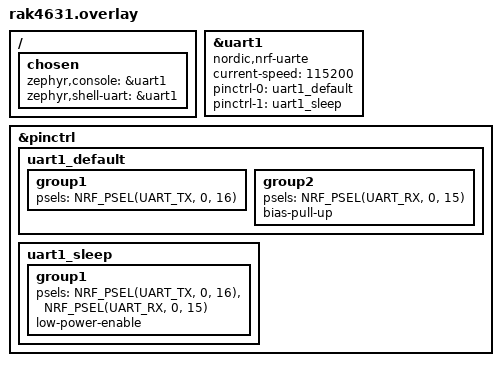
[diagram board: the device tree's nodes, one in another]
/*
 * Motor driver test - Node (Link) Y channel
 * Console: uart1 (P0.16 TX / P0.15 RX) @ 115200 → ttyUSB0
 *
 * Y channel:
 *   Y_EN_A  = P0.25
 *   Y_EN_B  = P1.01
 *   Y_EN_P2 = P1.02 (반드시 LOW 유지)
 *   12V_EN  = P0.17
 *
 * 참고: link.h
 */

/ {
	chosen {
		zephyr,console = &uart1;
		zephyr,shell-uart = &uart1;
	};
};

&uart1 {
	compatible = "nordic,nrf-uarte";
	status = "okay";
	current-speed = <115200>;
	pinctrl-0 = <&uart1_default>;
	pinctrl-1 = <&uart1_sleep>;
	pinctrl-names = "default", "sleep";
};

&pinctrl {
	uart1_default: uart1_default {
		group1 {
			psels = <NRF_PSEL(UART_TX, 0, 16)>;
		};
		group2 {
			psels = <NRF_PSEL(UART_RX, 0, 15)>;
			bias-pull-up;
		};
	};

	uart1_sleep: uart1_sleep {
		group1 {
			psels = <NRF_PSEL(UART_TX, 0, 16)>,
				<NRF_PSEL(UART_RX, 0, 15)>;
			low-power-enable;
		};
	};
};
